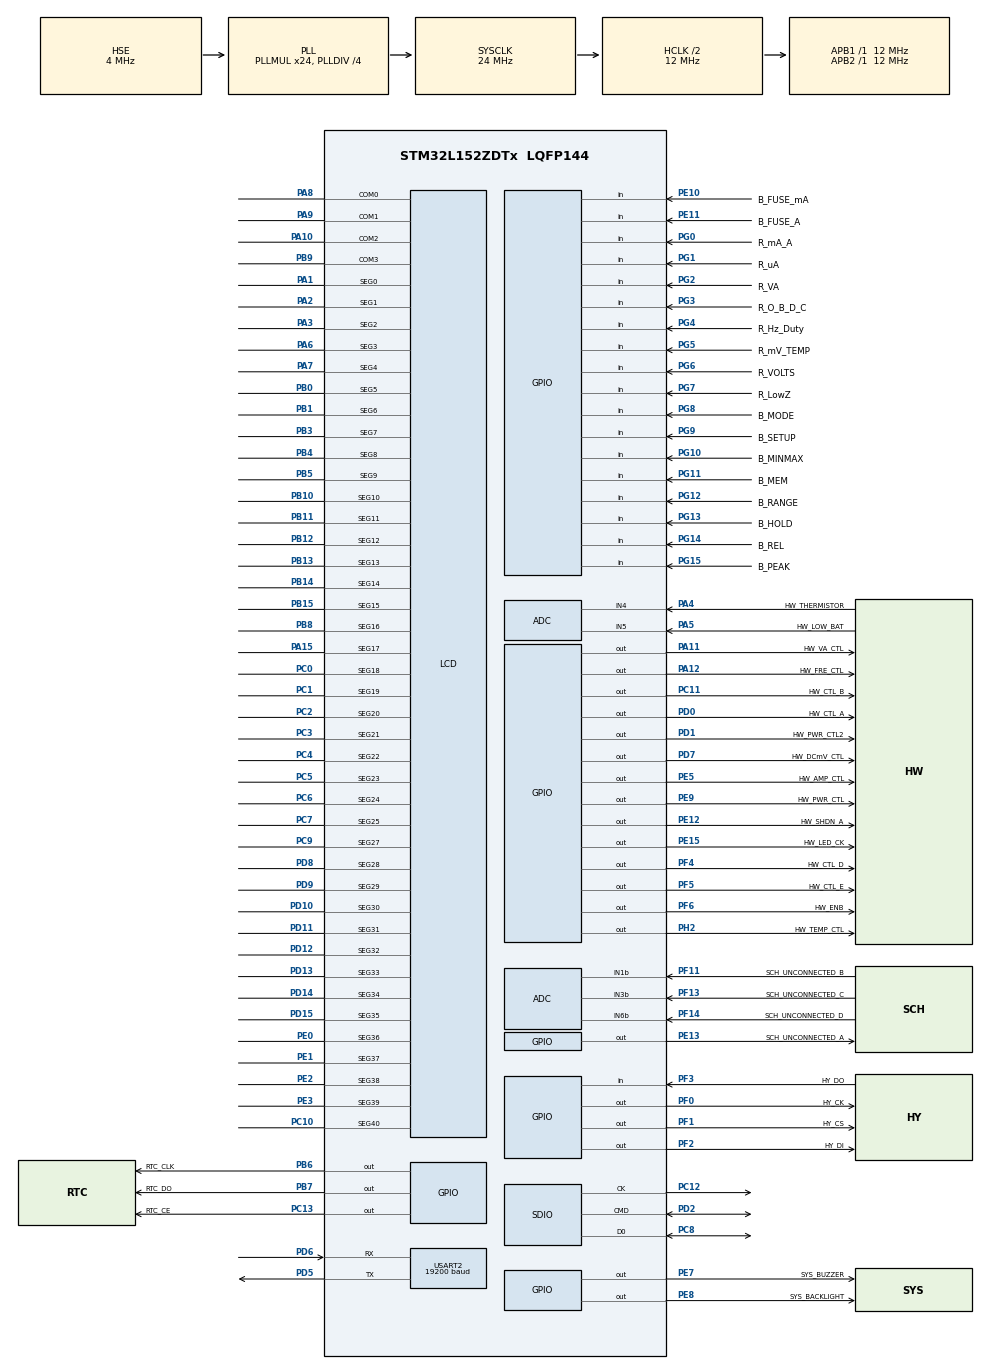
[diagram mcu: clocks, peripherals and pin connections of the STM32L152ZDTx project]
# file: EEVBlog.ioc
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ADC.Channel-16\#ChannelRegularConversion=ADC_CHANNEL_4
ADC.NbrOfConversionFlag=1
ADC.Rank-16\#ChannelRegularConversion=1
ADC.SamplingTime-16\#ChannelRegularConversion=ADC_SAMPLETIME_4CYCLES
Dma.Request0=SD/MMC
Dma.SD/MMC.0.Direction=DMA_PERIPH_TO_MEMORY
Dma.SD/MMC.0.Instance=DMA2_Channel4
Dma.SD/MMC.0.MemDataAlignment=DMA_MDATAALIGN_WORD
Dma.SD/MMC.0.MemInc=DMA_MINC_ENABLE
Dma.SD/MMC.0.Mode=DMA_NORMAL
Dma.SD/MMC.0.PeriphDataAlignment=DMA_PDATAALIGN_WORD
Dma.SD/MMC.0.PeriphInc=DMA_PINC_DISABLE
Dma.SD/MMC.0.Priority=DMA_PRIORITY_LOW
FATFS._FS_LOCK=0
FATFS._FS_MINIMIZE=2
FATFS._FS_TINY=1
FATFS._STRF_ENCODE=0
FATFS._USE_ERASE=0
FATFS._USE_MKFS=0
LCD.Bias=LCD_BIAS_1_3
LCD.BlinkFrequency=LCD_BLINKFREQUENCY_DIV128
LCD.Contrast=LCD_CONTRASTLEVEL_5
LCD.HighDrive=DISABLE
LCD.Prescaler=LCD_PRESCALER_8
LCD.PulseOnDuration=LCD_PULSEONDURATION_4
Mcu.Family=STM32L1
Mcu.Name=STM32L152ZDTx
Mcu.Package=LQFP144
NVIC.DMA2_Channel4_IRQn=true\:0\:0\:false\:false\:true\:true
NVIC.PriorityGroup=NVIC_PRIORITYGROUP_4
PA1.GPIO_Speed=GPIO_SPEED_FREQ_LOW
PA1.Mode=SEG0
PA1.Signal=LCD_SEG0
PA10.GPIO_Speed=GPIO_SPEED_FREQ_LOW
PA10.Mode=1/4 Duty Cycle
PA10.Signal=LCD_COM2
PA11.GPIO_Label=HW_VA_CTL
PA11.GPIO_Speed=GPIO_SPEED_FREQ_MEDIUM
PA11.Signal=GPIO_Output
PA12.GPIO_Label=HW_FRE_CTL
PA12.GPIO_Speed=GPIO_SPEED_FREQ_MEDIUM
PA12.PinState=GPIO_PIN_SET
PA12.Signal=GPIO_Output
PA13.Mode=Serial_Wire
PA13.Signal=SYS_JTMS-SWDIO
PA14.Mode=Serial_Wire
PA14.Signal=SYS_JTCK-SWCLK
PA15.GPIO_Speed=GPIO_SPEED_FREQ_LOW
PA15.Mode=SEG17
PA15.Signal=LCD_SEG17
PA2.GPIO_Speed=GPIO_SPEED_FREQ_LOW
PA2.Mode=SEG1
PA2.Signal=LCD_SEG1
PA3.GPIO_Speed=GPIO_SPEED_FREQ_LOW
PA3.Mode=SEG2
PA3.Signal=LCD_SEG2
PA4.GPIO_Label=HW_THERMISTOR
PA4.Mode=IN4
PA4.Signal=ADC_IN4
PA5.GPIO_Label=HW_LOW_BAT
PA5.Mode=IN5
PA5.Signal=ADC_IN5
PA6.GPIO_Speed=GPIO_SPEED_FREQ_LOW
PA6.Mode=SEG3
PA6.Signal=LCD_SEG3
PA7.GPIO_Speed=GPIO_SPEED_FREQ_LOW
PA7.Mode=SEG4
PA7.Signal=LCD_SEG4
PA8.GPIO_Speed=GPIO_SPEED_FREQ_LOW
PA8.Mode=1/4 Duty Cycle
PA8.Signal=LCD_COM0
PA9.GPIO_Speed=GPIO_SPEED_FREQ_LOW
PA9.Mode=1/4 Duty Cycle
PA9.Signal=LCD_COM1
PB0.GPIO_Speed=GPIO_SPEED_FREQ_LOW
PB0.Mode=SEG5
PB0.Signal=LCD_SEG5
PB1.GPIO_Speed=GPIO_SPEED_FREQ_LOW
PB1.Mode=SEG6
PB1.Signal=LCD_SEG6
PB10.GPIO_Speed=GPIO_SPEED_FREQ_LOW
PB10.Mode=SEG10
PB10.Signal=LCD_SEG10
PB11.GPIO_Speed=GPIO_SPEED_FREQ_LOW
PB11.Mode=SEG11
PB11.Signal=LCD_SEG11
PB12.GPIO_Speed=GPIO_SPEED_FREQ_LOW
PB12.Mode=SEG12
PB12.Signal=LCD_SEG12
PB13.GPIO_Speed=GPIO_SPEED_FREQ_LOW
PB13.Mode=SEG13
PB13.Signal=LCD_SEG13
PB14.GPIO_Speed=GPIO_SPEED_FREQ_LOW
PB14.Mode=SEG14
PB14.Signal=LCD_SEG14
PB15.GPIO_Speed=GPIO_SPEED_FREQ_LOW
PB15.Mode=SEG15
PB15.Signal=LCD_SEG15
PB3.GPIO_Speed=GPIO_SPEED_FREQ_LOW
PB3.Mode=SEG7
PB3.Signal=LCD_SEG7
PB4.GPIO_Speed=GPIO_SPEED_FREQ_LOW
PB4.Mode=SEG8
PB4.Signal=LCD_SEG8
PB5.GPIO_Speed=GPIO_SPEED_FREQ_LOW
PB5.Mode=SEG9
PB5.Signal=LCD_SEG9
PB6.GPIO_Label=RTC_CLK
PB6.GPIO_Speed=GPIO_SPEED_FREQ_VERY_HIGH
PB6.PinState=GPIO_PIN_SET
PB6.Signal=GPIO_Output
PB7.GPIO_Label=RTC_DO
PB7.GPIO_Speed=GPIO_SPEED_FREQ_VERY_HIGH
PB7.PinState=GPIO_PIN_RESET
PB7.Signal=GPIO_Output
PB8.GPIO_Speed=GPIO_SPEED_FREQ_LOW
PB8.Mode=SEG16
PB8.Signal=LCD_SEG16
PB9.GPIO_Speed=GPIO_SPEED_FREQ_LOW
PB9.Mode=1/4 Duty Cycle
PB9.Signal=LCD_COM3
PC0.GPIO_Speed=GPIO_SPEED_FREQ_LOW
PC0.Mode=SEG18
PC0.Signal=LCD_SEG18
PC1.GPIO_Speed=GPIO_SPEED_FREQ_LOW
PC1.Mode=SEG19
PC1.Signal=LCD_SEG19
PC10.GPIO_Speed=GPIO_SPEED_FREQ_LOW
PC10.Mode=SEG40
PC10.Signal=LCD_SEG40
PC11.GPIO_Label=HW_CTL_B
PC11.GPIO_Speed=GPIO_SPEED_FREQ_MEDIUM
PC11.Signal=GPIO_Output
PC12.Mode=SD_1_bit
PC12.Signal=SDIO_CK
PC13-WKUP2.GPIO_Label=RTC_CE
PC13-WKUP2.GPIO_Speed=GPIO_SPEED_FREQ_VERY_HIGH
PC13-WKUP2.PinState=GPIO_PIN_SET
PC13-WKUP2.Signal=GPIO_Output
PC2.GPIO_Speed=GPIO_SPEED_FREQ_LOW
PC2.Mode=SEG20
PC2.Signal=LCD_SEG20
PC3.GPIO_Speed=GPIO_SPEED_FREQ_LOW
PC3.Mode=SEG21
PC3.Signal=LCD_SEG21
PC4.GPIO_Speed=GPIO_SPEED_FREQ_LOW
PC4.Mode=SEG22
PC4.Signal=LCD_SEG22
PC5.GPIO_Speed=GPIO_SPEED_FREQ_LOW
PC5.Mode=SEG23
PC5.Signal=LCD_SEG23
PC6.GPIO_Speed=GPIO_SPEED_FREQ_LOW
PC6.Mode=SEG24
PC6.Signal=LCD_SEG24
PC7.GPIO_Speed=GPIO_SPEED_FREQ_LOW
PC7.Mode=SEG25
PC7.Signal=LCD_SEG25
PC8.Mode=SD_1_bit
PC8.Signal=SDIO_D0
PC9.GPIO_Speed=GPIO_SPEED_FREQ_LOW
PC9.Mode=SEG27
PC9.Signal=LCD_SEG27
PD0.GPIO_Label=HW_CTL_A
PD0.GPIO_Speed=GPIO_SPEED_FREQ_MEDIUM
PD0.Signal=GPIO_Output
PD1.GPIO_Label=HW_PWR_CTL2
PD1.GPIO_Speed=GPIO_SPEED_FREQ_MEDIUM
PD1.Signal=GPIO_Output
PD10.GPIO_Speed=GPIO_SPEED_FREQ_LOW
PD10.Mode=SEG30
PD10.Signal=LCD_SEG30
PD11.GPIO_Speed=GPIO_SPEED_FREQ_LOW
PD11.Mode=SEG31
PD11.Signal=LCD_SEG31
PD12.GPIO_Speed=GPIO_SPEED_FREQ_LOW
PD12.Mode=SEG32
PD12.Signal=LCD_SEG32
PD13.GPIO_Speed=GPIO_SPEED_FREQ_LOW
PD13.Mode=SEG33
PD13.Signal=LCD_SEG33
PD14.GPIO_Speed=GPIO_SPEED_FREQ_LOW
PD14.Mode=SEG34
PD14.Signal=LCD_SEG34
PD15.GPIO_Speed=GPIO_SPEED_FREQ_LOW
PD15.Mode=SEG35
PD15.Signal=LCD_SEG35
PD2.Mode=SD_1_bit
PD2.Signal=SDIO_CMD
PD5.Mode=Asynchronous
PD5.Signal=USART2_TX
PD6.Mode=Asynchronous
PD6.Signal=USART2_RX
PD7.GPIO_Label=HW_DCmV_CTL
PD7.GPIO_Speed=GPIO_SPEED_FREQ_MEDIUM
PD7.PinState=GPIO_PIN_SET
PD7.Signal=GPIO_Output
PD8.GPIO_Speed=GPIO_SPEED_FREQ_LOW
PD8.Mode=SEG28
PD8.Signal=LCD_SEG28
PD9.GPIO_Speed=GPIO_SPEED_FREQ_LOW
PD9.Mode=SEG29
PD9.Signal=LCD_SEG29
PE0.GPIO_Speed=GPIO_SPEED_FREQ_LOW
PE0.Mode=SEG36
PE0.Signal=LCD_SEG36
PE1.GPIO_Speed=GPIO_SPEED_FREQ_LOW
PE1.Mode=SEG37
PE1.Signal=LCD_SEG37
PE10.GPIO_Label=B_FUSE_mA
PE10.Signal=GPIO_Input
PE11.GPIO_Label=B_FUSE_A
PE11.Signal=GPIO_Input
PE12.GPIO_Label=HW_SHDN_A
PE12.GPIO_Speed=GPIO_SPEED_FREQ_MEDIUM
PE12.Signal=GPIO_Output
PE13.GPIO_Label=SCH_UNCONNECTED_A
PE13.GPIO_Speed=GPIO_SPEED_FREQ_MEDIUM
PE13.Signal=GPIO_Output
PE15.GPIO_Label=HW_LED_CK
PE15.GPIO_Speed=GPIO_SPEED_FREQ_MEDIUM
PE15.Signal=GPIO_Output
PE2.GPIO_Speed=GPIO_SPEED_FREQ_LOW
PE2.Mode=SEG38
PE2.Signal=LCD_SEG38
PE3.GPIO_Speed=GPIO_SPEED_FREQ_LOW
PE3.Mode=SEG39
PE3.Signal=LCD_SEG39
PE5.GPIO_Label=HW_AMP_CTL
PE5.GPIO_Speed=GPIO_SPEED_FREQ_MEDIUM
PE5.Signal=GPIO_Output
PE7.GPIO_Label=SYS_BUZZER
PE7.GPIO_Speed=GPIO_SPEED_FREQ_MEDIUM
PE7.Signal=GPIO_Output
PE8.GPIO_Label=SYS_BACKLIGHT
PE8.GPIO_Speed=GPIO_SPEED_FREQ_MEDIUM
PE8.PinState=GPIO_PIN_RESET
PE8.Signal=GPIO_Output
PE9.GPIO_Label=HW_PWR_CTL
PE9.GPIO_Speed=GPIO_SPEED_FREQ_MEDIUM
PE9.PinState=GPIO_PIN_SET
PE9.Signal=GPIO_Output
PF0.GPIO_Label=HY_CK
PF0.GPIO_Speed=GPIO_SPEED_FREQ_VERY_HIGH
PF0.Signal=GPIO_Output
PF1.GPIO_Label=HY_CS
PF1.GPIO_Speed=GPIO_SPEED_FREQ_VERY_HIGH
PF1.Signal=GPIO_Output
PF11.GPIO_Label=SCH_UNCONNECTED_B
PF11.Mode=IN1b
PF11.Signal=ADC_IN1b
PF13.GPIO_Label=SCH_UNCONNECTED_C
PF13.Mode=IN3b
PF13.Signal=ADC_IN3b
PF14.GPIO_Label=SCH_UNCONNECTED_D
PF14.Mode=IN6b
PF14.Signal=ADC_IN6b
PF2.GPIO_Label=HY_DI
PF2.GPIO_Speed=GPIO_SPEED_FREQ_VERY_HIGH
PF2.PinState=GPIO_PIN_SET
PF2.Signal=GPIO_Output
PF3.GPIO_Label=HY_DO
PF3.Signal=GPIO_Input
PF4.GPIO_Label=HW_CTL_D
PF4.GPIO_Speed=GPIO_SPEED_FREQ_MEDIUM
PF4.Signal=GPIO_Output
PF5.GPIO_Label=HW_CTL_E
PF5.GPIO_Speed=GPIO_SPEED_FREQ_MEDIUM
PF5.Signal=GPIO_Output
PF6.GPIO_Label=HW_ENB
PF6.GPIO_Speed=GPIO_SPEED_FREQ_MEDIUM
PF6.Signal=GPIO_Output
PG0.GPIO_Label=R_mA_A
PG0.GPIO_PuPd=GPIO_PULLUP
PG0.Signal=GPIO_Input
PG1.GPIO_Label=R_uA
PG1.GPIO_PuPd=GPIO_PULLUP
PG1.Signal=GPIO_Input
PG10.GPIO_Label=B_MINMAX
PG10.GPIO_PuPd=GPIO_PULLUP
PG10.Signal=GPIO_Input
PG11.GPIO_Label=B_MEM
PG11.GPIO_PuPd=GPIO_PULLUP
PG11.Signal=GPIO_Input
PG12.GPIO_Label=B_RANGE
PG12.GPIO_PuPd=GPIO_PULLUP
PG12.Signal=GPIO_Input
PG13.GPIO_Label=B_HOLD
PG13.GPIO_PuPd=GPIO_PULLUP
PG13.Signal=GPIO_Input
PG14.GPIO_Label=B_REL
PG14.GPIO_PuPd=GPIO_PULLUP
PG14.Signal=GPIO_Input
PG15.GPIO_Label=B_PEAK
PG15.GPIO_PuPd=GPIO_PULLUP
PG15.Signal=GPIO_Input
PG2.GPIO_Label=R_VA
PG2.GPIO_PuPd=GPIO_PULLUP
PG2.Signal=GPIO_Input
PG3.GPIO_Label=R_O_B_D_C
PG3.GPIO_PuPd=GPIO_PULLUP
PG3.Signal=GPIO_Input
PG4.GPIO_Label=R_Hz_Duty
PG4.GPIO_PuPd=GPIO_PULLUP
PG4.Signal=GPIO_Input
PG5.GPIO_Label=R_mV_TEMP
PG5.GPIO_PuPd=GPIO_PULLUP
PG5.Signal=GPIO_Input
PG6.GPIO_Label=R_VOLTS
PG6.GPIO_PuPd=GPIO_PULLUP
PG6.Signal=GPIO_Input
PG7.GPIO_Label=R_LowZ
PG7.GPIO_PuPd=GPIO_PULLUP
PG7.Signal=GPIO_Input
PG8.GPIO_Label=B_MODE
PG8.GPIO_PuPd=GPIO_PULLUP
PG8.Signal=GPIO_Input
PG9.GPIO_Label=B_SETUP
PG9.GPIO_PuPd=GPIO_PULLUP
PG9.Signal=GPIO_Input
PH0-OSC_IN.Mode=HSE-External-Oscillator
PH0-OSC_IN.Signal=RCC_OSC_IN
PH1-OSC_OUT.Mode=HSE-External-Oscillator
PH1-OSC_OUT.Signal=RCC_OSC_OUT
PH2.GPIO_Label=HW_TEMP_CTL
PH2.GPIO_Speed=GPIO_SPEED_FREQ_MEDIUM
PH2.Signal=GPIO_Output
ProjectManager.HeapSize=0x200
ProjectManager.StackSize=0x400
ProjectManager.TargetToolchain=SW4STM32
RCC.48MHZClocksFreq_Value=48000000
RCC.AHBCLKDivider=RCC_SYSCLK_DIV2
RCC.AHBFreq_Value=12000000
RCC.APB1Freq_Value=12000000
RCC.APB1TimFreq_Value=12000000
RCC.APB2Freq_Value=12000000
RCC.APB2TimFreq_Value=12000000
RCC.HCLKFreq_Value=12000000
RCC.HSE_VALUE=4000000
RCC.HSI_VALUE=16000000
RCC.LSE_VALUE=32768
RCC.MSI_VALUE=2097000
RCC.PLLDIV=RCC_PLL_DIV4
RCC.PLLMUL=RCC_PLL_MUL24
RCC.PLLSourceVirtual=RCC_PLLSOURCE_HSE
RCC.PREFETCH_ENABLE=0
RCC.PWR_Regulator_Voltage_Scale=PWR_REGULATOR_VOLTAGE_SCALE1
RCC.RCC_RTC_Clock_Source_FROM_HSE=RCC_RTCCLKSOURCE_HSE_DIV16
RCC.SYSCLKFreq_VALUE=24000000
RCC.SYSCLKSource=RCC_SYSCLKSOURCE_PLLCLK
RCC.USBOutput=24000000
RCC.VCOOutputFreq_Value=96000000
SDIO.ClockBypass=SDIO_CLOCK_BYPASS_DISABLE
SDIO.ClockEdge=SDIO_CLOCK_EDGE_RISING
SDIO.ClockPowerSave=SDIO_CLOCK_POWER_SAVE_ENABLE
SDIO.HardwareFlowControl=SDIO_HARDWARE_FLOW_CONTROL_DISABLE
USART2.BaudRate=19200
USART2.HwFlowCtl-Asynchronous=UART_HWCONTROL_NONE
USART2.VirtualMode=VM_ASYNC
VP_FATFS_VS_SDIO.Mode=SDIO
VP_RTC_VS_RTC_Activate.Mode=RTC_Enabled
board=EEVBlog

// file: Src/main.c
/**
  ******************************************************************************
  * @file           : main.c
  * @brief          : Main program body
  ******************************************************************************
  * This notice applies to any and all portions of this file
  * that are not between comment pairs USER CODE BEGIN and
  * USER CODE END. Other portions of this file, whether
  * inserted by the user or by software development tools
  * are owned by their respective copyright owners.
  *
  * Copyright (c) 2018 STMicroelectronics International N.V.
  * All rights reserved.
  *
  * Redistribution and use in source and binary forms, with or without
  * modification, are permitted, provided that the following conditions are met:
  *
  * 1. Redistribution of source code must retain the above copyright notice,
  *    this list of conditions and the following disclaimer.
  * 2. Redistributions in binary form must reproduce the above copyright notice,
  *    this list of conditions and the following disclaimer in the documentation
  *    and/or other materials provided with the distribution.
  * 3. Neither the name of STMicroelectronics nor the names of other
  *    contributors to this software may be used to endorse or promote products
  *    derived from this software without specific written permission.
  * 4. This software, including modifications and/or derivative works of this
  *    software, must execute solely and exclusively on microcontroller or
  *    microprocessor devices manufactured by or for STMicroelectronics.
  * 5. Redistribution and use of this software other than as permitted under
  *    this license is void and will automatically terminate your rights under
  *    this license.
  *
  * THIS SOFTWARE IS PROVIDED BY STMICROELECTRONICS AND CONTRIBUTORS "AS IS"
  * AND ANY EXPRESS, IMPLIED OR STATUTORY WARRANTIES, INCLUDING, BUT NOT
  * LIMITED TO, THE IMPLIED WARRANTIES OF MERCHANTABILITY, FITNESS FOR A
  * PARTICULAR PURPOSE AND NON-INFRINGEMENT OF THIRD PARTY INTELLECTUAL PROPERTY
  * RIGHTS ARE DISCLAIMED TO THE FULLEST EXTENT PERMITTED BY LAW. IN NO EVENT
  * SHALL STMICROELECTRONICS OR CONTRIBUTORS BE LIABLE FOR ANY DIRECT, INDIRECT,
  * INCIDENTAL, SPECIAL, EXEMPLARY, OR CONSEQUENTIAL DAMAGES (INCLUDING, BUT NOT
  * LIMITED TO, PROCUREMENT OF SUBSTITUTE GOODS OR SERVICES; LOSS OF USE, DATA,
  * OR PROFITS; OR BUSINESS INTERRUPTION) HOWEVER CAUSED AND ON ANY THEORY OF
  * LIABILITY, WHETHER IN CONTRACT, STRICT LIABILITY, OR TORT (INCLUDING
  * NEGLIGENCE OR OTHERWISE) ARISING IN ANY WAY OUT OF THE USE OF THIS SOFTWARE,
  * EVEN IF ADVISED OF THE POSSIBILITY OF SUCH DAMAGE.
  *
  ******************************************************************************
  */
#include "main.h"
#include "stm32l1xx_hal.h"
#include "fatfs.h"

/* USER CODE BEGIN Includes */

#include "system/system.h"

/* USER CODE END Includes */

ADC_HandleTypeDef hadc;

LCD_HandleTypeDef hlcd;

RTC_HandleTypeDef hrtc;

SD_HandleTypeDef hsd;
HAL_SD_CardInfoTypedef SDCardInfo;
DMA_HandleTypeDef hdma_sd_mmc;

UART_HandleTypeDef huart2;

/* USER CODE BEGIN PV */
/* Private variables ---------------------------------------------------------*/

/* USER CODE END PV */

void SystemClock_Config(void);
static void MX_GPIO_Init(void);
static void MX_DMA_Init(void);
static void MX_LCD_Init(void);
static void MX_SDIO_SD_Init(void);
static void MX_USART2_UART_Init(void);
static void MX_ADC_Init(void);
static void MX_RTC_Init(void);

/* USER CODE BEGIN PFP */
/* Private function prototypes -----------------------------------------------*/

/* USER CODE END PFP */

int main(void)
{
  /* USER CODE BEGIN 1 */

  // the bootloader leaves a mess which we need to clean up
  {
    // reset all peripherals
    HAL_DeInit();
    // disable and un-pend all NVIC interrupts
    for (int i=0; i<=2; i++) {
      NVIC->ICER[i] = 0xFFFFFFFF;
      NVIC->ICPR[i] = 0xFFFFFFFF;
    }
    // relocate vector table to us instead of the bootloader
    SCB->VTOR = 0x8006000;
  }

  /* USER CODE END 1 */

  /* MCU Configuration----------------------------------------------------------*/

  /* Reset of all peripherals, Initializes the Flash interface and the Systick. */
  HAL_Init();

  /* Configure the system clock */
  SystemClock_Config();

  /* Initialize all configured peripherals */
  MX_GPIO_Init();
  MX_DMA_Init();
  MX_LCD_Init();
  MX_SDIO_SD_Init();
  MX_FATFS_Init();
  MX_USART2_UART_Init();
  MX_ADC_Init();
  MX_RTC_Init();
  /* USER CODE BEGIN 2 */

  sys_main_loop();

  /* USER CODE END 2 */

  /* Infinite loop */
  while (1)
  {

  }

}

void SystemClock_Config(void)
{

  RCC_OscInitTypeDef RCC_OscInitStruct;
  RCC_ClkInitTypeDef RCC_ClkInitStruct;
  RCC_PeriphCLKInitTypeDef PeriphClkInit;

    /**Configure the main internal regulator output voltage
    */
  __HAL_PWR_VOLTAGESCALING_CONFIG(PWR_REGULATOR_VOLTAGE_SCALE1);

    /**Initializes the CPU, AHB and APB busses clocks
    */
  RCC_OscInitStruct.OscillatorType = RCC_OSCILLATORTYPE_HSI|RCC_OSCILLATORTYPE_LSI
                              |RCC_OSCILLATORTYPE_HSE;
  RCC_OscInitStruct.HSEState = RCC_HSE_ON;
  RCC_OscInitStruct.HSIState = RCC_HSI_ON;
  RCC_OscInitStruct.HSICalibrationValue = 16;
  RCC_OscInitStruct.LSIState = RCC_LSI_ON;
  RCC_OscInitStruct.PLL.PLLState = RCC_PLL_ON;
  RCC_OscInitStruct.PLL.PLLSource = RCC_PLLSOURCE_HSE;
  RCC_OscInitStruct.PLL.PLLMUL = RCC_PLL_MUL24;
  RCC_OscInitStruct.PLL.PLLDIV = RCC_PLL_DIV4;
  if (HAL_RCC_OscConfig(&RCC_OscInitStruct) != HAL_OK)
  {
    _Error_Handler(__FILE__, __LINE__);
  }

    /**Initializes the CPU, AHB and APB busses clocks
    */
  RCC_ClkInitStruct.ClockType = RCC_CLOCKTYPE_HCLK|RCC_CLOCKTYPE_SYSCLK
                              |RCC_CLOCKTYPE_PCLK1|RCC_CLOCKTYPE_PCLK2;
  RCC_ClkInitStruct.SYSCLKSource = RCC_SYSCLKSOURCE_PLLCLK;
  RCC_ClkInitStruct.AHBCLKDivider = RCC_SYSCLK_DIV2;
  RCC_ClkInitStruct.APB1CLKDivider = RCC_HCLK_DIV1;
  RCC_ClkInitStruct.APB2CLKDivider = RCC_HCLK_DIV1;

  if (HAL_RCC_ClockConfig(&RCC_ClkInitStruct, FLASH_LATENCY_0) != HAL_OK)
  {
    _Error_Handler(__FILE__, __LINE__);
  }

  PeriphClkInit.PeriphClockSelection = RCC_PERIPHCLK_RTC|RCC_PERIPHCLK_LCD;
  PeriphClkInit.RTCClockSelection = RCC_RTCCLKSOURCE_LSI;
  PeriphClkInit.LCDClockSelection = RCC_RTCCLKSOURCE_LSI;

  if (HAL_RCCEx_PeriphCLKConfig(&PeriphClkInit) != HAL_OK)
  {
    _Error_Handler(__FILE__, __LINE__);
  }

    /**Configure the Systick interrupt time
    */
  HAL_SYSTICK_Config(HAL_RCC_GetHCLKFreq()/1000);

    /**Configure the Systick
    */
  HAL_SYSTICK_CLKSourceConfig(SYSTICK_CLKSOURCE_HCLK);

  /* SysTick_IRQn interrupt configuration */
  HAL_NVIC_SetPriority(SysTick_IRQn, 0, 0);
}

/* ADC init function */
static void MX_ADC_Init(void)
{

  ADC_ChannelConfTypeDef sConfig;

    /**Configure the global features of the ADC (Clock, Resolution, Data Alignment and number of conversion)
    */
  hadc.Instance = ADC1;
  hadc.Init.ClockPrescaler = ADC_CLOCK_ASYNC_DIV1;
  hadc.Init.Resolution = ADC_RESOLUTION_12B;
  hadc.Init.DataAlign = ADC_DATAALIGN_RIGHT;
  hadc.Init.ScanConvMode = ADC_SCAN_DISABLE;
  hadc.Init.EOCSelection = ADC_EOC_SEQ_CONV;
  hadc.Init.LowPowerAutoWait = ADC_AUTOWAIT_DISABLE;
  hadc.Init.LowPowerAutoPowerOff = ADC_AUTOPOWEROFF_DISABLE;
  hadc.Init.ChannelsBank = ADC_CHANNELS_BANK_A;
  hadc.Init.ContinuousConvMode = DISABLE;
  hadc.Init.NbrOfConversion = 1;
  hadc.Init.DiscontinuousConvMode = DISABLE;
  hadc.Init.ExternalTrigConv = ADC_SOFTWARE_START;
  hadc.Init.ExternalTrigConvEdge = ADC_EXTERNALTRIGCONVEDGE_NONE;
  hadc.Init.DMAContinuousRequests = DISABLE;
  if (HAL_ADC_Init(&hadc) != HAL_OK)
  {
    _Error_Handler(__FILE__, __LINE__);
  }

    /**Configure for the selected ADC regular channel its corresponding rank in the sequencer and its sample time.
    */
  sConfig.Channel = ADC_CHANNEL_4;
  sConfig.Rank = ADC_REGULAR_RANK_1;
  sConfig.SamplingTime = ADC_SAMPLETIME_4CYCLES;
  if (HAL_ADC_ConfigChannel(&hadc, &sConfig) != HAL_OK)
  {
    _Error_Handler(__FILE__, __LINE__);
  }

}

/* LCD init function */
static void MX_LCD_Init(void)
{

  hlcd.Instance = LCD;
  hlcd.Init.Prescaler = LCD_PRESCALER_8;
  hlcd.Init.Divider = LCD_DIVIDER_16;
  hlcd.Init.Duty = LCD_DUTY_1_4;
  hlcd.Init.Bias = LCD_BIAS_1_3;
  hlcd.Init.VoltageSource = LCD_VOLTAGESOURCE_INTERNAL;
  hlcd.Init.Contrast = LCD_CONTRASTLEVEL_5;
  hlcd.Init.DeadTime = LCD_DEADTIME_0;
  hlcd.Init.PulseOnDuration = LCD_PULSEONDURATION_4;
  hlcd.Init.MuxSegment = LCD_MUXSEGMENT_DISABLE;
  hlcd.Init.BlinkMode = LCD_BLINKMODE_OFF;
  hlcd.Init.BlinkFrequency = LCD_BLINKFREQUENCY_DIV128;
  if (HAL_LCD_Init(&hlcd) != HAL_OK)
  {
    _Error_Handler(__FILE__, __LINE__);
  }

}

/* RTC init function */
static void MX_RTC_Init(void)
{

    /**Initialize RTC Only
    */
  hrtc.Instance = RTC;
  hrtc.Init.HourFormat = RTC_HOURFORMAT_24;
  hrtc.Init.AsynchPrediv = 127;
  hrtc.Init.SynchPrediv = 255;
  hrtc.Init.OutPut = RTC_OUTPUT_DISABLE;
  hrtc.Init.OutPutPolarity = RTC_OUTPUT_POLARITY_HIGH;
  hrtc.Init.OutPutType = RTC_OUTPUT_TYPE_OPENDRAIN;
  if (HAL_RTC_Init(&hrtc) != HAL_OK)
  {
    _Error_Handler(__FILE__, __LINE__);
  }

}

/* SDIO init function */
static void MX_SDIO_SD_Init(void)
{

  hsd.Instance = SDIO;
  hsd.Init.ClockEdge = SDIO_CLOCK_EDGE_RISING;
  hsd.Init.ClockBypass = SDIO_CLOCK_BYPASS_DISABLE;
  hsd.Init.ClockPowerSave = SDIO_CLOCK_POWER_SAVE_ENABLE;
  hsd.Init.BusWide = SDIO_BUS_WIDE_1B;
  hsd.Init.HardwareFlowControl = SDIO_HARDWARE_FLOW_CONTROL_DISABLE;
  hsd.Init.ClockDiv = 0;

}

/* USART2 init function */
static void MX_USART2_UART_Init(void)
{

  huart2.Instance = USART2;
  huart2.Init.BaudRate = 19200;
  huart2.Init.WordLength = UART_WORDLENGTH_8B;
  huart2.Init.StopBits = UART_STOPBITS_1;
  huart2.Init.Parity = UART_PARITY_NONE;
  huart2.Init.Mode = UART_MODE_TX_RX;
  huart2.Init.HwFlowCtl = UART_HWCONTROL_NONE;
  huart2.Init.OverSampling = UART_OVERSAMPLING_16;
  if (HAL_UART_Init(&huart2) != HAL_OK)
  {
    _Error_Handler(__FILE__, __LINE__);
  }

}

static void MX_DMA_Init(void)
{
  /* DMA controller clock enable */
  __HAL_RCC_DMA2_CLK_ENABLE();

  /* DMA interrupt init */
  /* DMA2_Channel4_IRQn interrupt configuration */
  HAL_NVIC_SetPriority(DMA2_Channel4_IRQn, 0, 0);
  HAL_NVIC_EnableIRQ(DMA2_Channel4_IRQn);

}

/** Configure pins as
        * Analog
        * Input
        * Output
        * EVENT_OUT
        * EXTI
*/
static void MX_GPIO_Init(void)
{

  GPIO_InitTypeDef GPIO_InitStruct;

  /* GPIO Ports Clock Enable */
  __HAL_RCC_GPIOE_CLK_ENABLE();
  __HAL_RCC_GPIOC_CLK_ENABLE();
  __HAL_RCC_GPIOF_CLK_ENABLE();
  __HAL_RCC_GPIOH_CLK_ENABLE();
  __HAL_RCC_GPIOA_CLK_ENABLE();
  __HAL_RCC_GPIOB_CLK_ENABLE();
  __HAL_RCC_GPIOG_CLK_ENABLE();
  __HAL_RCC_GPIOD_CLK_ENABLE();

  /*Configure GPIO pin Output Level */
  HAL_GPIO_WritePin(GPIOE, HW_AMP_CTL_Pin|SYS_BUZZER_Pin|SYS_BACKLIGHT_Pin|HW_SHDN_A_Pin
                          |SCH_UNCONNECTED_A_Pin|HW_LED_CK_Pin, GPIO_PIN_RESET);

  /*Configure GPIO pin Output Level */
  HAL_GPIO_WritePin(RTC_CE_GPIO_Port, RTC_CE_Pin, GPIO_PIN_SET);

  /*Configure GPIO pin Output Level */
  HAL_GPIO_WritePin(GPIOF, HY_CK_Pin|HY_CS_Pin|HW_CTL_D_Pin|HW_CTL_E_Pin
                          |HW_ENB_Pin, GPIO_PIN_RESET);

  /*Configure GPIO pin Output Level */
  HAL_GPIO_WritePin(HY_DI_GPIO_Port, HY_DI_Pin, GPIO_PIN_SET);

  /*Configure GPIO pin Output Level */
  HAL_GPIO_WritePin(HW_PWR_CTL_GPIO_Port, HW_PWR_CTL_Pin, GPIO_PIN_SET);

  /*Configure GPIO pin Output Level */
  HAL_GPIO_WritePin(HW_VA_CTL_GPIO_Port, HW_VA_CTL_Pin, GPIO_PIN_RESET);

  /*Configure GPIO pin Output Level */
  HAL_GPIO_WritePin(HW_FRE_CTL_GPIO_Port, HW_FRE_CTL_Pin, GPIO_PIN_SET);

  /*Configure GPIO pin Output Level */
  HAL_GPIO_WritePin(HW_TEMP_CTL_GPIO_Port, HW_TEMP_CTL_Pin, GPIO_PIN_RESET);

  /*Configure GPIO pin Output Level */
  HAL_GPIO_WritePin(HW_CTL_B_GPIO_Port, HW_CTL_B_Pin, GPIO_PIN_RESET);

  /*Configure GPIO pin Output Level */
  HAL_GPIO_WritePin(GPIOD, HW_CTL_A_Pin|HW_PWR_CTL2_Pin, GPIO_PIN_RESET);

  /*Configure GPIO pin Output Level */
  HAL_GPIO_WritePin(HW_DCmV_CTL_GPIO_Port, HW_DCmV_CTL_Pin, GPIO_PIN_SET);

  /*Configure GPIO pin Output Level */
  HAL_GPIO_WritePin(RTC_CLK_GPIO_Port, RTC_CLK_Pin, GPIO_PIN_SET);

  /*Configure GPIO pin Output Level */
  HAL_GPIO_WritePin(RTC_DO_GPIO_Port, RTC_DO_Pin, GPIO_PIN_RESET);

  /*Configure GPIO pins : HW_AMP_CTL_Pin SYS_BUZZER_Pin SYS_BACKLIGHT_Pin HW_PWR_CTL_Pin
                           HW_SHDN_A_Pin SCH_UNCONNECTED_A_Pin HW_LED_CK_Pin */
  GPIO_InitStruct.Pin = HW_AMP_CTL_Pin|SYS_BUZZER_Pin|SYS_BACKLIGHT_Pin|HW_PWR_CTL_Pin
                          |HW_SHDN_A_Pin|SCH_UNCONNECTED_A_Pin|HW_LED_CK_Pin;
  GPIO_InitStruct.Mode = GPIO_MODE_OUTPUT_PP;
  GPIO_InitStruct.Pull = GPIO_NOPULL;
  GPIO_InitStruct.Speed = GPIO_SPEED_FREQ_MEDIUM;
  HAL_GPIO_Init(GPIOE, &GPIO_InitStruct);

  /*Configure GPIO pin : RTC_CE_Pin */
  GPIO_InitStruct.Pin = RTC_CE_Pin;
  GPIO_InitStruct.Mode = GPIO_MODE_OUTPUT_PP;
  GPIO_InitStruct.Pull = GPIO_NOPULL;
  GPIO_InitStruct.Speed = GPIO_SPEED_FREQ_VERY_HIGH;
  HAL_GPIO_Init(RTC_CE_GPIO_Port, &GPIO_InitStruct);

  /*Configure GPIO pins : HY_CK_Pin HY_CS_Pin HY_DI_Pin */
  GPIO_InitStruct.Pin = HY_CK_Pin|HY_CS_Pin|HY_DI_Pin;
  GPIO_InitStruct.Mode = GPIO_MODE_OUTPUT_PP;
  GPIO_InitStruct.Pull = GPIO_NOPULL;
  GPIO_InitStruct.Speed = GPIO_SPEED_FREQ_VERY_HIGH;
  HAL_GPIO_Init(GPIOF, &GPIO_InitStruct);

  /*Configure GPIO pin : HY_DO_Pin */
  GPIO_InitStruct.Pin = HY_DO_Pin;
  GPIO_InitStruct.Mode = GPIO_MODE_INPUT;
  GPIO_InitStruct.Pull = GPIO_NOPULL;
  HAL_GPIO_Init(HY_DO_GPIO_Port, &GPIO_InitStruct);

  /*Configure GPIO pins : HW_CTL_D_Pin HW_CTL_E_Pin HW_ENB_Pin */
  GPIO_InitStruct.Pin = HW_CTL_D_Pin|HW_CTL_E_Pin|HW_ENB_Pin;
  GPIO_InitStruct.Mode = GPIO_MODE_OUTPUT_PP;
  GPIO_InitStruct.Pull = GPIO_NOPULL;
  GPIO_InitStruct.Speed = GPIO_SPEED_FREQ_MEDIUM;
  HAL_GPIO_Init(GPIOF, &GPIO_InitStruct);

  /*Configure GPIO pins : R_mA_A_Pin R_uA_Pin R_VA_Pin R_O_B_D_C_Pin
                           R_Hz_Duty_Pin R_mV_TEMP_Pin R_VOLTS_Pin R_LowZ_Pin
                           B_MODE_Pin B_SETUP_Pin B_MINMAX_Pin B_MEM_Pin
                           B_RANGE_Pin B_HOLD_Pin B_REL_Pin B_PEAK_Pin */
  GPIO_InitStruct.Pin = R_mA_A_Pin|R_uA_Pin|R_VA_Pin|R_O_B_D_C_Pin
                          |R_Hz_Duty_Pin|R_mV_TEMP_Pin|R_VOLTS_Pin|R_LowZ_Pin
                          |B_MODE_Pin|B_SETUP_Pin|B_MINMAX_Pin|B_MEM_Pin
                          |B_RANGE_Pin|B_HOLD_Pin|B_REL_Pin|B_PEAK_Pin;
  GPIO_InitStruct.Mode = GPIO_MODE_INPUT;
  GPIO_InitStruct.Pull = GPIO_PULLUP;
  HAL_GPIO_Init(GPIOG, &GPIO_InitStruct);

  /*Configure GPIO pins : B_FUSE_mA_Pin B_FUSE_A_Pin */
  GPIO_InitStruct.Pin = B_FUSE_mA_Pin|B_FUSE_A_Pin;
  GPIO_InitStruct.Mode = GPIO_MODE_INPUT;
  GPIO_InitStruct.Pull = GPIO_NOPULL;
  HAL_GPIO_Init(GPIOE, &GPIO_InitStruct);

  /*Configure GPIO pins : HW_VA_CTL_Pin HW_FRE_CTL_Pin */
  GPIO_InitStruct.Pin = HW_VA_CTL_Pin|HW_FRE_CTL_Pin;
  GPIO_InitStruct.Mode = GPIO_MODE_OUTPUT_PP;
  GPIO_InitStruct.Pull = GPIO_NOPULL;
  GPIO_InitStruct.Speed = GPIO_SPEED_FREQ_MEDIUM;
  HAL_GPIO_Init(GPIOA, &GPIO_InitStruct);

  /*Configure GPIO pin : HW_TEMP_CTL_Pin */
  GPIO_InitStruct.Pin = HW_TEMP_CTL_Pin;
  GPIO_InitStruct.Mode = GPIO_MODE_OUTPUT_PP;
  GPIO_InitStruct.Pull = GPIO_NOPULL;
  GPIO_InitStruct.Speed = GPIO_SPEED_FREQ_MEDIUM;
  HAL_GPIO_Init(HW_TEMP_CTL_GPIO_Port, &GPIO_InitStruct);

  /*Configure GPIO pin : HW_CTL_B_Pin */
  GPIO_InitStruct.Pin = HW_CTL_B_Pin;
  GPIO_InitStruct.Mode = GPIO_MODE_OUTPUT_PP;
  GPIO_InitStruct.Pull = GPIO_NOPULL;
  GPIO_InitStruct.Speed = GPIO_SPEED_FREQ_MEDIUM;
  HAL_GPIO_Init(HW_CTL_B_GPIO_Port, &GPIO_InitStruct);

  /*Configure GPIO pins : HW_CTL_A_Pin HW_PWR_CTL2_Pin HW_DCmV_CTL_Pin */
  GPIO_InitStruct.Pin = HW_CTL_A_Pin|HW_PWR_CTL2_Pin|HW_DCmV_CTL_Pin;
  GPIO_InitStruct.Mode = GPIO_MODE_OUTPUT_PP;
  GPIO_InitStruct.Pull = GPIO_NOPULL;
  GPIO_InitStruct.Speed = GPIO_SPEED_FREQ_MEDIUM;
  HAL_GPIO_Init(GPIOD, &GPIO_InitStruct);

  /*Configure GPIO pins : RTC_CLK_Pin RTC_DO_Pin */
  GPIO_InitStruct.Pin = RTC_CLK_Pin|RTC_DO_Pin;
  GPIO_InitStruct.Mode = GPIO_MODE_OUTPUT_PP;
  GPIO_InitStruct.Pull = GPIO_NOPULL;
  GPIO_InitStruct.Speed = GPIO_SPEED_FREQ_VERY_HIGH;
  HAL_GPIO_Init(GPIOB, &GPIO_InitStruct);

}

void _Error_Handler(char *file, int line)
{
  while(1)
  {
  }
}

/************************ (C) COPYRIGHT STMicroelectronics *****END OF FILE****/
